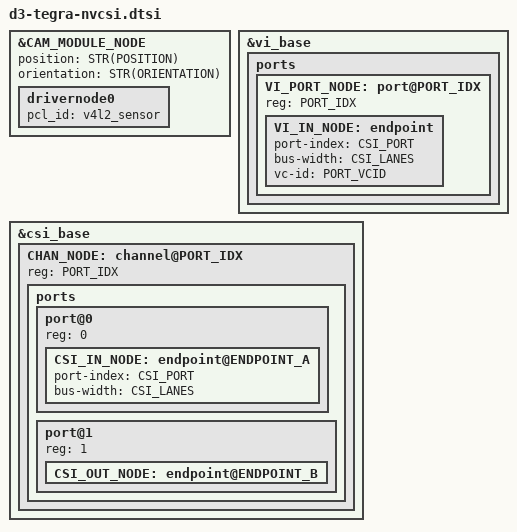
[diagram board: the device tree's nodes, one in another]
/*
 * Copyright (c) 2019, D3 Engineering. All rights reserved.
 *
 * This program is free software; you can redistribute it and/or modify
 * it under the terms of the GNU General Public License as published by
 * the Free Software Foundation; version 2 of the License.
 *
 * This program is distributed in the hope that it will be useful, but WITHOUT
 * ANY WARRANTY; without even the implied warranty of MERCHANTABILITY or
 * FITNESS FOR A PARTICULAR PURPOSE.  See the GNU General Public License for
 * more details.
 */

// Compatibility for where port_idx corresponds to csi_port
#ifndef PORT_IDX
#	define PORT_IDX CSI_PORT
#endif

#define VI_PORT_NODE CONCAT_2(vi_port_,PORT_IDX)
#define VI_IN_NODE CONCAT_2(vi_in_,PORT_IDX)
#define CHAN_NODE CONCAT_2(chan_,PORT_IDX)
#define CSI_IN_NODE CONCAT_2(csi_in_,PORT_IDX)
#define CSI_OUT_NODE CONCAT_2(csi_out_,PORT_IDX)
#define CAM_MODULE_NODE CONCAT_2(cam_module, PORT_IDX)

&CAM_MODULE_NODE {
	position = STR(POSITION);
	status = STR(STATUS);
	orientation = STR(ORIENTATION);

        drivernode0 {
		pcl_id = "v4l2_sensor";
		status = STR(STATUS);
	};
};

&vi_base {
	ports {
		#address-cells = <1>;
		#size-cells = <0>;
		VI_PORT_NODE: port@PORT_IDX {
			status = STR(STATUS);
			reg = <PORT_IDX>;
			VI_IN_NODE: endpoint {
				status = STR(STATUS);
				port-index = <CSI_PORT>;
				bus-width = <CSI_LANES>;
				vc-id = <PORT_VCID>;
			};
		};
	};
};

&csi_base {
	CHAN_NODE: channel@PORT_IDX {
		status = STR(STATUS);
		reg = <PORT_IDX>;
		ports {
			#address-cells = <1>;
			#size-cells = <0>;
			port@0 {
				status = STR(STATUS);
				reg = <0>;
				CSI_IN_NODE: endpoint@ENDPOINT_A {
					status = STR(STATUS);
					port-index = <CSI_PORT>;
					bus-width = <CSI_LANES>;
				};
			};
			port@1 {
				status = STR(STATUS);
				reg = <1>;
				CSI_OUT_NODE: endpoint@ENDPOINT_B {
					status = STR(STATUS);
				};
			};
		};
	};
};
